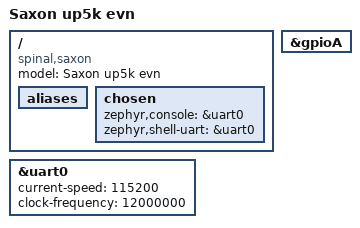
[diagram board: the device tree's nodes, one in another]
/*
 * Copyright (c) 2018 Linaro Limited
 *
 * SPDX-License-Identifier: Apache-2.0
 */

/dts-v1/;

#include <vexriscv_saxon_soc.dtsi>

/ {
	model = "Saxon up5k evn";
	compatible = "spinal,saxon";
	aliases {
	};

	chosen {
		zephyr,console = &uart0;
		zephyr,shell-uart = &uart0;
	};
};

&gpioA {
	status = "ok";
};


&uart0 {
	status = "ok";
	current-speed = <115200>;
	clock-frequency = <12000000>;
};

